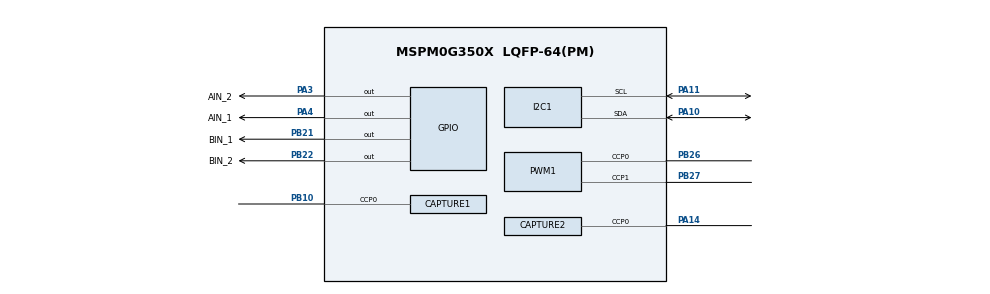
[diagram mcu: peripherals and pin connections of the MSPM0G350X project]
/**
 *
 * @cliArgs --device "MSPM0G350X" --part "Default" --package "LQFP-64(PM)" --product "mspm0_sdk@2.11.00.07"
 * @versions {"tool":"1.28.0+4712"}
 */

/**
 * Import the modules used in this configuration.
 */
const CAPTURE  = scripting.addModule("/ti/driverlib/CAPTURE", {}, false);
const CAPTURE1 = CAPTURE.addInstance();
const CAPTURE2 = CAPTURE.addInstance();
const GPIO     = scripting.addModule("/ti/driverlib/GPIO", {}, false);
const GPIO1    = GPIO.addInstance();
const GPIO2    = GPIO.addInstance();
const GPIO3    = GPIO.addInstance();
const I2C      = scripting.addModule("/ti/driverlib/I2C", {}, false);
const I2C1     = I2C.addInstance();
const PWM      = scripting.addModule("/ti/driverlib/PWM", {}, false);
const PWM1     = PWM.addInstance();
const SYSCTL   = scripting.addModule("/ti/driverlib/SYSCTL");
const UART     = scripting.addModule("/ti/driverlib/UART", {}, false);
const UART1    = UART.addInstance();

/**
 * Write custom configuration values to the imported modules.
 */
const divider9       = system.clockTree["UDIV"];
divider9.divideValue = 2;

const gate7  = system.clockTree["MFCLKGATE"];
gate7.enable = true;

const multiplier2         = system.clockTree["PLL_QDIV"];
multiplier2.multiplyValue = 4;

const mux4       = system.clockTree["EXHFMUX"];
mux4.inputSelect = "EXHFMUX_XTAL";

const mux8       = system.clockTree["HSCLKMUX"];
mux8.inputSelect = "HSCLKMUX_SYSPLL0";

const mux12       = system.clockTree["SYSPLLMUX"];
mux12.inputSelect = "zSYSPLLMUX_HFCLK";

const pinFunction4        = system.clockTree["HFXT"];
pinFunction4.inputFreq    = 40;
pinFunction4.enable       = true;
pinFunction4.HFXTStartup  = 10;
pinFunction4.HFCLKMonitor = true;

CAPTURE1.$name                            = "CAP_A";
CAPTURE1.interrupts                       = ["CC0_DN"];
CAPTURE1.timerPeriod                      = "625.2 us";
CAPTURE1.peripheral.$assignAllowConflicts = "TIMG0";
CAPTURE1.peripheral.ccp0Pin.$assign       = "PB10";
CAPTURE1.ccp0PinConfig.$name              = "ti_driverlib_gpio_GPIOPinGeneric6";

const Board = scripting.addModule("/ti/driverlib/Board", {}, false);

CAPTURE2.interrupts                 = ["CC0_DN"];
CAPTURE2.$name                      = "CAP_B";
CAPTURE2.timerPeriod                = "625.2 us";
CAPTURE2.peripheral.$assign         = "TIMG12";
CAPTURE2.peripheral.ccp0Pin.$assign = "PA14";
CAPTURE2.ccp0PinConfig.$name        = "ti_driverlib_gpio_GPIOPinGeneric7";

GPIO1.$name                         = "GPIO_LEDS";
GPIO1.port                          = "PORTA";
GPIO1.associatedPins.create(2);
GPIO1.associatedPins[0].$name       = "USER_LED_1";
GPIO1.associatedPins[0].assignedPin = "2";
GPIO1.associatedPins[1].$name       = "USER_LED_2";
GPIO1.associatedPins[1].assignedPin = "7";

GPIO2.$name                         = "A_DIRECT";
GPIO2.port                          = "PORTA";
GPIO2.associatedPins.create(2);
GPIO2.associatedPins[0].$name       = "AIN_1";
GPIO2.associatedPins[0].pin.$assign = "PA4";
GPIO2.associatedPins[1].$name       = "AIN_2";
GPIO2.associatedPins[1].pin.$assign = "PA3";

GPIO3.$name                         = "B_DIRECT";
GPIO3.port                          = "PORTB";
GPIO3.associatedPins.create(2);
GPIO3.associatedPins[0].$name       = "BIN_1";
GPIO3.associatedPins[0].pin.$assign = "PB21";
GPIO3.associatedPins[1].$name       = "BIN_2";
GPIO3.associatedPins[1].pin.$assign = "PB22";

I2C1.$name                     = "I2C_0";
I2C1.basicEnableController     = true;
I2C1.peripheral.sdaPin.$assign = "PA10";
I2C1.peripheral.sclPin.$assign = "PA11";
I2C1.sdaPinConfig.$name        = "ti_driverlib_gpio_GPIOPinGeneric0";
I2C1.sdaPinConfig.enableConfig = true;
I2C1.sclPinConfig.$name        = "ti_driverlib_gpio_GPIOPinGeneric1";
I2C1.sclPinConfig.enableConfig = true;

PWM1.timerCount                         = 999;
PWM1.$name                              = "PWM_A_B";
PWM1.peripheral.$assign                 = "TIMG6";
PWM1.peripheral.ccp0Pin.$assign         = "PB26";
PWM1.peripheral.ccp1Pin.$assign         = "PB27";
PWM1.PWM_CHANNEL_0.$name                = "ti_driverlib_pwm_PWMTimerCC0";
PWM1.PWM_CHANNEL_0.shadowUpdateMode     = "ZERO_EVT";
PWM1.PWM_CHANNEL_1.$name                = "ti_driverlib_pwm_PWMTimerCC1";
PWM1.PWM_CHANNEL_1.shadowUpdateMode     = "ZERO_EVT";
PWM1.ccp0PinConfig.$name                = "ti_driverlib_gpio_GPIOPinGeneric4";
PWM1.ccp0PinConfig.direction            = scripting.forceWrite("OUTPUT");
PWM1.ccp0PinConfig.hideOutputInversion  = scripting.forceWrite(false);
PWM1.ccp0PinConfig.onlyInternalResistor = scripting.forceWrite(false);
PWM1.ccp0PinConfig.passedPeripheralType = scripting.forceWrite("Digital");
PWM1.ccp0PinConfig.enableConfig         = true;
PWM1.ccp1PinConfig.$name                = "ti_driverlib_gpio_GPIOPinGeneric5";
PWM1.ccp1PinConfig.direction            = scripting.forceWrite("OUTPUT");
PWM1.ccp1PinConfig.hideOutputInversion  = scripting.forceWrite(false);
PWM1.ccp1PinConfig.onlyInternalResistor = scripting.forceWrite(false);
PWM1.ccp1PinConfig.passedPeripheralType = scripting.forceWrite("Digital");
PWM1.ccp1PinConfig.enableConfig         = true;

SYSCTL.clockTreeEn     = true;
SYSCTL.useHFCLK_Manual = true;

UART1.$name             = "UART_0";
UART1.txPinConfig.$name = "ti_driverlib_gpio_GPIOPinGeneric2";
UART1.rxPinConfig.$name = "ti_driverlib_gpio_GPIOPinGeneric3";

/**
 * Pinmux solution for unlocked pins/peripherals. This ensures that minor changes to the automatic solver in a future
 * version of the tool will not impact the pinmux you originally saw.  These lines can be completely deleted in order to
 * re-solve from scratch.
 */
pinFunction4.peripheral.$suggestSolution           = "SYSCTL";
pinFunction4.peripheral.hfxInPin.$suggestSolution  = "PA5";
pinFunction4.peripheral.hfxOutPin.$suggestSolution = "PA6";
Board.peripheral.$suggestSolution                  = "DEBUGSS";
Board.peripheral.swclkPin.$suggestSolution         = "PA20";
Board.peripheral.swdioPin.$suggestSolution         = "PA19";
GPIO1.associatedPins[0].pin.$suggestSolution       = "PA2";
GPIO1.associatedPins[1].pin.$suggestSolution       = "PA7";
I2C1.peripheral.$suggestSolution                   = "I2C0";
UART1.peripheral.$suggestSolution                  = "UART0";
UART1.peripheral.rxPin.$suggestSolution            = "PA1";
UART1.peripheral.txPin.$suggestSolution            = "PA0";
